# nrf7140_radiocore register map
Vendor: Nordic Semiconductor; Series: nRF71; File version: 1
CPU: CM33 r0p4, little endian, MPU, FPU, 3 interrupt priority bits, 480 interrupts, 8 SAU regions
Registers are 32-bit, read-write, reset 0x0 unless marked. A register's access mark holds for its fields unless they carry their own. Offsets are from the block's base; [hi:lo] are bit positions; lines under a group give offsets from that group; {n}, {i} and the like mark numbered series.

## RAMC000_NS — RAM Controller 0
Base 0x43004000
Same registers: RAMC001_NS 0x43038000, RAMC000_S 0x53004000, RAMC001_S 0x53038000
0x500 WAITSTATES — Waitstates for read operations.
  [0] WAITSTATES — Number of waitstates for a read from the RAM.
0x600 SECBASE — Base address for secure access area.
  [31:0] ADDR — Base address
0x604 SECENABLE — Enable secure access restrictions.
  [0] ENABLE — Enable secure access restrictions
    0=Disable (Secure access restrictions disabled); 1=Enable (Secure access restrictions enabled)

## GLOBAL_PCGCSBUS_NS — PCGCSlave
Base 0x4900CF00; alternate view of GLOBAL_GFXPLLPM_NS
Same registers: PCGCS000_S 0x5300C000, PCGCS010_S 0x5301D000, PCGCS020_S 0x53021000, PCGCS030_S 0x5303E000
{0xC00+4i} PENALTY[{i}] (i=0..1) reset 0xFFFFFFFC — Description collection: Penalty level for power/clock pair n. When FULL_PCP_ZERO feature is not supported, PENALTY[0] address overlaps the PENALTY0 address and register description for PENALTY[0] is not valid.
  [1:0] PENALTY — Penalty level
0xC00 PENALTY0 (alternate view of PENALTY[*]) — Penalty level for power/clock pair 0. The register description is valid only when FULL_PCP_ZERO feature is not supported
  [1:0] PENALTY ro — Penalty level
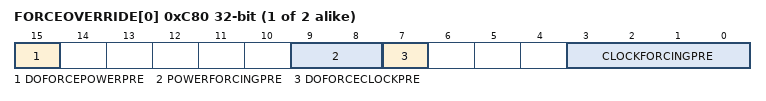
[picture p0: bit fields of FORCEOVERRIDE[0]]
{0xC80+4i} FORCEOVERRIDE[{i}] (i=0..1) — Description collection: Force override of power/clock pair n.
  [15] DOFORCEPOWERPRE, [9:8] POWERFORCINGPRE, [7] DOFORCECLOCKPRE, [3:0] CLOCKFORCINGPRE

## GLOBAL_PCGCM300_NS — PCGC Master 0
Base 0x4900F000
Same registers: GLOBAL_PCGCM310_NS 0x4901F000, PCGCM000_S 0x5300F000, PCGCM010_S 0x5301F000, PCGCM020_S 0x5302F000, PCGCM030_S 0x5303F000
{0xE0+4i} SETPWRCONTHRESHOLDBASE[{i}] (i=0..2) — Description collection: Set power consumption threshold base for power source / regulator n
  [3:0] SETPWRCONTHRESHOLDBASE
0xC00 UNLOCKBACKDOORS
  [15:0] UNLOCKBACKDOORS — Write: 0x00009375 to lock/unlock backdoors Read: 0x00000001 if backdoors is enabled Read: 0x00000000 if backdoors is disabled
0xC04 ENABLEPOWERREGFORCE
  [2:0] ENABLEPOWERREGFORCE
0xC08 POWERREGFORCE — Force reg
  [2:0] POWERREGFORCEREG
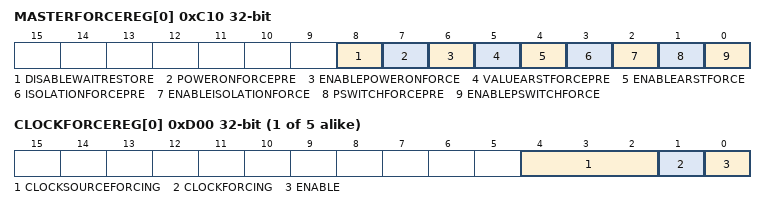
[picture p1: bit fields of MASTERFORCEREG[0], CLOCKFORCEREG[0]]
{0xC10+4i} MASTERFORCEREG[{i}] (i=0..0) — Description collection: Force reg
  [8] DISABLEWAITRESTORE — Turn off waiting for arst deactivation before retention restore
    1=Disable (Turn off waiting for arst deactivation before retention restore); 0=Enable (Wait for arst deactivation before retention restore)
  [7] POWERONFORCEPRE
  [6] ENABLEPOWERONFORCE
  [5] VALUEARSTFORCEPRE
  [4] ENABLEARSTFORCE
  [3] ISOLATIONFORCEPRE
  [2] ENABLEISOLATIONFORCE
  [1] PSWITCHFORCEPRE
  [0] ENABLEPSWITCHFORCE
{0xD00+4i} CLOCKFORCEREG[{i}] (i=0..4) — Description collection: Force clock n
  [4:2] CLOCKSOURCEFORCING
  [1] CLOCKFORCING
  [0] ENABLE — Enable clock forcing

## CPUCONF_NS — CPU Configuration 0
Base 0x43011000
Same registers: CPUCONF_S 0x53011000
0x00 TASKS_ERASECACHE wo — Erase the caches used by the CPU.
  [0] TASKS_ERASECACHE
    1=Trigger task
0x500 INITSVTOR — Initial value of the secure VTOR (Vector Table Offset Register) after CPU reset.
  [31:0] INITSVTOR — Initial value of the VTOR.
0x504 INITNSVTOR — Initial value of the non-secure VTOR (Vector Table Offset Register).
  [31:0] INITNSVTOR — Initial value of the VTOR.
0x508 CPUSTART — Enable for starting the CPU
  [0] EN — Enable to start the CPU.
    0=Stopped (CPU stopped.); 1=Started (CPU started.)
0x50C CPUWAIT — Enable for the CPU wait.
  [0] EN — Enable to the CPU wait.
    0=Disabled (CPU is not waiting.); 1=Enabled (CPU is waiting.)

## GLOBAL_MEMCONF310_NS — Memory configuration
Base 0x49011000
Same registers: MEMCONF_NS 0x43012000, MEMCONF_S 0x53012000
{0x500+0x10*i} POWER[{i}] (i=0..1) group — Unspecified
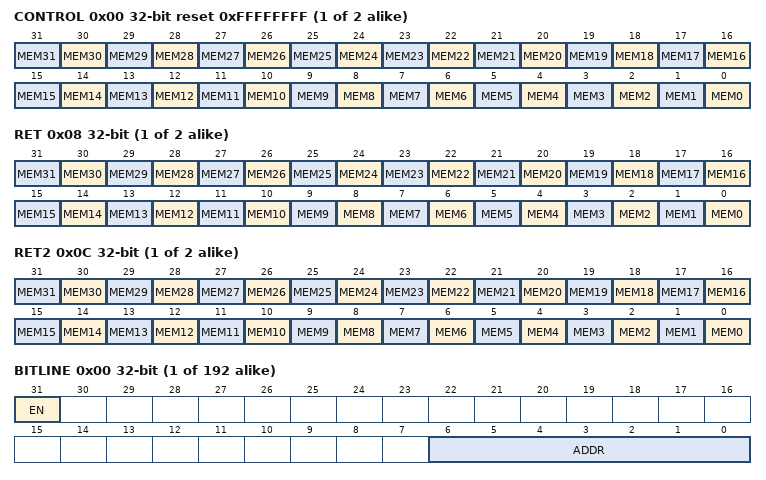
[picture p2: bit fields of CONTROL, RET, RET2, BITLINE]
  0x00 CONTROL reset 0xFFFFFFFF — Description cluster: Control memory block power.
    [all] fields
      0=Off (Power down); 1=On (Power up)
    [n] MEM{n} (n=0..31) — Keep the memory block MEM[{n}] on or off when in System ON mode.
  0x08 RET — Description cluster: RAM retention for RAM [n].
    [all] fields
      0=Off (Retention off); 1=On (Retention on)
    [n] MEM{n} (n=0..31) — Keep the RAM block MEM[{n}] retained when the parent power domain of the RAM is off.
  0x0C RET2 — Description cluster: RAM retention for the second bank in the RAM block
    [all] fields
      0=Off (Retention off); 1=On (Retention on)
    [n] MEM{n} (n=0..31) — Keep the second bank in RAM block MEM[{n}] retained when parent power domain of the RAM is off.
{0x600+4i} REPAIR[{i}] (i=0..191) group — Unspecified
  0x00 BITLINE — Description cluster: Repair configuration for RAM blocks.
    [31] EN — Enable bitline repair
      0=Disabled (Repair disabled.); 1=Enabled (Repair enabled.)
    [6:0] ADDR — Repair address of the bitline
{0x900+4i} BLOCKTYPE[{i}] (i=0..63) group — Unspecified
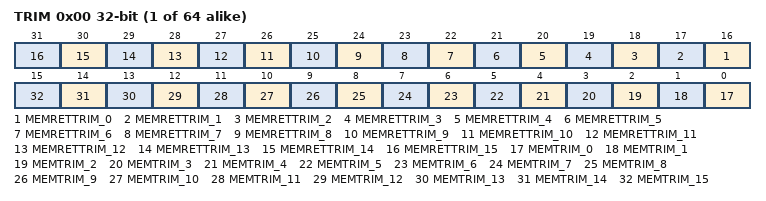
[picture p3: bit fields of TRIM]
  0x00 TRIM — Description cluster: Trim configuration for the memory block types.
    [n+16] MEMRETTRIM_{n} (n=0..15) — Trimming for retention mode for decreased leakage. Must be kept active in RAM retention mode.
    [n] MEMTRIM_{n} (n=0..15) — Read/write margin trim.

## Notices in the file
Copyright (c) 2010 - 2024, Nordic Semiconductor ASA
All rights reserved.
Redistribution and use in source and binary forms, with or without modification,
are permitted provided that the following conditions are met:
1. Redistributions of source code must retain the above copyright notice, this
list of conditions and the following disclaimer.
2. Redistributions in binary form, except as embedded into a Nordic
Semiconductor ASA integrated circuit in a product or a software update for
such product, must reproduce the above copyright notice, this list of
conditions and the following disclaimer in the documentation and/or other
materials provided with the distribution.
3. Neither the name of Nordic Semiconductor ASA nor the names of its
contributors may be used to endorse or promote products derived from this
software without specific prior written permission.
4. This software, with or without modification, must only be used with a
Nordic Semiconductor ASA integrated circuit.
5. Any software provided in binary form under this license must not be reverse
engineered, decompiled, modified and/or disassembled.
THIS SOFTWARE IS PROVIDED BY NORDIC SEMICONDUCTOR ASA "AS IS" AND ANY EXPRESS
OR IMPLIED WARRANTIES, INCLUDING, BUT NOT LIMITED TO, THE IMPLIED WARRANTIES
OF MERCHANTABILITY, NONINFRINGEMENT, AND FITNESS FOR A PARTICULAR PURPOSE ARE
DISCLAIMED. IN NO EVENT SHALL NORDIC SEMICONDUCTOR ASA OR CONTRIBUTORS BE
LIABLE FOR ANY DIRECT, INDIRECT, INCIDENTAL, SPECIAL, EXEMPLARY, OR
CONSEQUENTIAL DAMAGES (INCLUDING, BUT NOT LIMITED TO, PROCUREMENT OF SUBSTITUTE
GOODS OR SERVICES; LOSS OF USE, DATA, OR PROFITS; OR BUSINESS INTERRUPTION)
HOWEVER CAUSED AND ON ANY THEORY OF LIABILITY, WHETHER IN CONTRACT, STRICT
LIABILITY, OR TORT (INCLUDING NEGLIGENCE OR OTHERWISE) ARISING IN ANY WAY OUT
OF THE USE OF THIS SOFTWARE, EVEN IF ADVISED OF THE POSSIBILITY OF SUCH DAMAGE.
